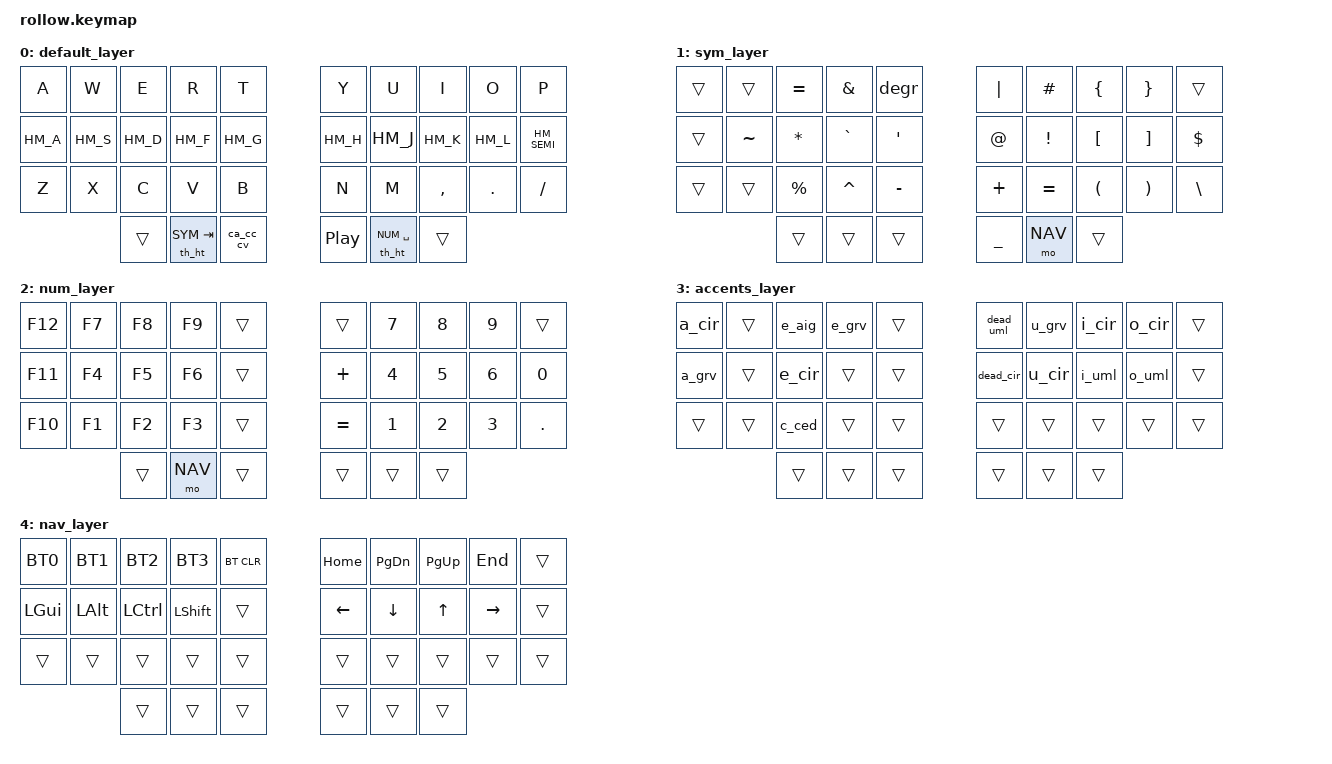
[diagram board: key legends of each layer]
#include <behaviors.dtsi>
#include <dt-bindings/zmk/keys.h>
#include <dt-bindings/zmk/bt.h>

#include "definitions.dtsi"
#include "homerow.dtsi"
#include "combos.dtsi"
#include "unicode.dtsi"
#include "tapdances.dtsi"

/ {
        chosen {
                zmk,matrix_transform = &five_column_transform;
        };

        keymap {
                compatible = "zmk,keymap";

                default_layer {
                        bindings = <
   &kp A &kp W &kp E &kp R &kp T   &kp Y &kp U  &kp I     &kp O   &kp P
   HM_A  HM_S  HM_D  HM_F  HM_G    HM_H  HM_J   HM_K      HM_L    HM_SEMI
   &kp Z &kp X &kp C &kp V &kp B   &kp N &kp M  &kp COMMA &kp DOT &kp FSLH
      &trans &th_ht SYM TAB &ca_cc_cv   &kp C_PP &th_ht NUM SPACE &trans
                        >;
                        sensor-bindings = <&inc_dec_kp C_VOL_UP C_VOL_DN &inc_dec_kp C_NEXT C_PREV>;
                };

                sym_layer {
                        bindings = <
   &trans       &trans     &kp EQUAL &kp AMPS  &degr      &kp PIPE &kp HASH  &kp LBRC &kp RBRC  &trans
   &trans       &kp TILDE  &kp STAR  &kp GRAVE &kp SQT    &kp AT   &kp EXCL  &kp LBKT &kp RBKT  &kp DLLR
   &trans       &trans     &kp PRCNT &kp CARET &kp MINUS  &kp PLUS &kp EQUAL &kp LPAR &kp RPAR  &kp BSLH
                           &trans    &trans    &trans     &kp UNDER &mo NAV  &trans
                        >;
                        sensor-bindings = <&inc_dec_kp DOWN UP &inc_dec_kp RIGHT LEFT>;
                };

                num_layer {
                        bindings = <
   &kp F12   &kp F7    &kp F8    &kp F9    &trans      &trans    &kp N7    &kp N8     &kp N9   &trans
   &kp F11   &kp F4    &kp F5    &kp F6    &trans      &kp PLUS  &kp N4    &kp N5     &kp N6   &kp N0
   &kp F10   &kp F1    &kp F2    &kp F3    &trans      &kp EQUAL &kp N1    &kp N2     &kp N3   &kp DOT
                       &trans    &mo NAV   &trans      &trans    &trans    &trans
                        >;
                        sensor-bindings = <&inc_dec_kp DOWN UP &inc_dec_kp RIGHT LEFT>;
                };

                accents_layer {
                        bindings = <
   &a_cir   &trans   &e_aig   &e_grv   &trans   &dead_uml   &u_grv   &i_cir   &o_cir   &trans
   &a_grv   &trans   &e_cir   &trans   &trans   &dead_cir   &u_cir   &i_uml   &o_uml   &trans
   &trans   &trans   &c_ced   &trans   &trans   &trans      &trans   &trans   &trans   &trans
                     &trans   &trans   &trans   &trans      &trans   &trans
                        >;
                };

                nav_layer {
                        bindings = <
   BT0        BT1        BT2        BT3       &bt BT_CLR  &kp HOME  &kp PG_DN &kp PG_UP &kp END   &trans
   &kp LGUI   &kp LALT   &kp LCTRL  &kp LSHFT &trans      &kp LEFT  &kp DOWN  &kp UP    &kp RIGHT &trans
   &trans     &trans     &trans     &trans    &trans      &trans    &trans    &trans    &trans    &trans
                         &trans     &trans    &trans      &trans    &trans    &trans
                         >;
                };
        };
};
